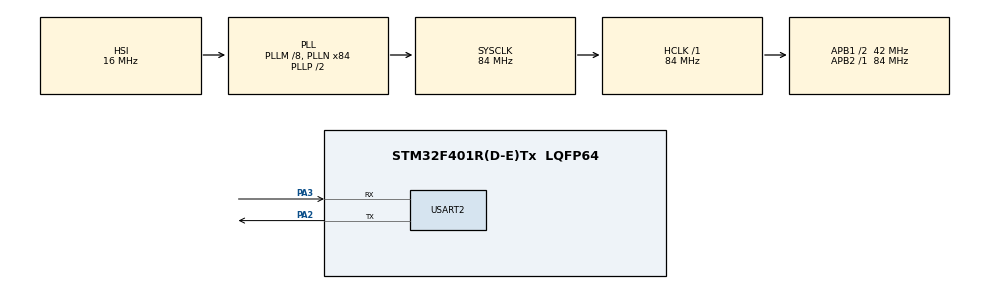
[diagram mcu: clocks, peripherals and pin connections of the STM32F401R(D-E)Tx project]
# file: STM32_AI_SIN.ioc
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Mcu.Family=STM32F4
Mcu.Name=STM32F401R(D-E)Tx
Mcu.Package=LQFP64
NVIC.PriorityGroup=NVIC_PRIORITYGROUP_4
NVIC.TIM1_TRG_COM_TIM11_IRQn=true\:0\:0\:false\:false\:true\:true\:true\:true
NVIC.USART2_IRQn=true\:0\:0\:false\:false\:true\:true\:true\:true
PA13.Mode=Serial_Wire
PA13.Signal=SYS_JTMS-SWDIO
PA14.Mode=Serial_Wire
PA14.Signal=SYS_JTCK-SWCLK
PA2.Mode=Asynchronous
PA2.Signal=USART2_TX
PA3.Mode=Asynchronous
PA3.Signal=USART2_RX
PH0\ -\ OSC_IN.Mode=HSE-External-Oscillator
PH0\ -\ OSC_IN.Signal=RCC_OSC_IN
PH1\ -\ OSC_OUT.Mode=HSE-External-Oscillator
PH1\ -\ OSC_OUT.Signal=RCC_OSC_OUT
ProjectManager.HeapSize=0x800
ProjectManager.StackSize=0x800
ProjectManager.TargetToolchain=STM32CubeIDE
RCC.48MHZClocksFreq_Value=42000000
RCC.AHBFreq_Value=84000000
RCC.APB1CLKDivider=RCC_HCLK_DIV2
RCC.APB1Freq_Value=42000000
RCC.APB1TimFreq_Value=84000000
RCC.APB2Freq_Value=84000000
RCC.APB2TimFreq_Value=84000000
RCC.CortexFreq_Value=84000000
RCC.HCLKFreq_Value=84000000
RCC.HSE_VALUE=25000000
RCC.HSI_VALUE=16000000
RCC.LSE_VALUE=32768
RCC.PLLM=8
RCC.PLLN=84
RCC.SYSCLKFreq_VALUE=84000000
RCC.SYSCLKSource=RCC_SYSCLKSOURCE_PLLCLK
RCC.VCOOutputFreq_Value=168000000
STMicroelectronics.X-CUBE-AI.8.1.0.ActivationBufferSizeList=4928
STMicroelectronics.X-CUBE-AI.8.1.0.ActivationBuffers=pool0
STMicroelectronics.X-CUBE-AI.8.1.0.ActivationNames=pool0
STMicroelectronics.X-CUBE-AI.8.1.0.ActivationSizes=AI_SINNET_DATA_ACTIVATION_1_SIZE
STMicroelectronics.X-CUBE-AI.8.1.0.HeapSize=0x800
STMicroelectronics.X-CUBE-AI.8.1.0.InternalRamActivationBufferMaxSize=AI_SINNET_DATA_ACTIVATIONS_SIZE
STMicroelectronics.X-CUBE-AI.8.1.0.LatestDirectoryUsed-b5e6d1a6911b70669444c67b1f081640bab3704ab8a9a7e3d65810467d735324=C\:\\Users\\danie\\OneDrive\\Desktop\\STM32_AI_SIN\\experiments\\run_12_12_2023__17_07_38
STMicroelectronics.X-CUBE-AI.8.1.0.MaximumNumberOfInputLayer=1
STMicroelectronics.X-CUBE-AI.8.1.0.MaximumNumberOfOutputLayer=1
STMicroelectronics.X-CUBE-AI.8.1.0.MaximumSizeOfInputLayer=1
STMicroelectronics.X-CUBE-AI.8.1.0.MaximumSizeOfOutputLayer=1
STMicroelectronics.X-CUBE-AI.8.1.0.ModelActualCompression-b5e6d1a6911b70669444c67b1f081640bab3704ab8a9a7e3d65810467d735324=0.0
STMicroelectronics.X-CUBE-AI.8.1.0.ModelCompression-b5e6d1a6911b70669444c67b1f081640bab3704ab8a9a7e3d65810467d735324=None
STMicroelectronics.X-CUBE-AI.8.1.0.ModelFlashOccupation-b5e6d1a6911b70669444c67b1f081640bab3704ab8a9a7e3d65810467d735324=92974
STMicroelectronics.X-CUBE-AI.8.1.0.ModelHashList=b5e6d1a6911b70669444c67b1f081640bab3704ab8a9a7e3d65810467d735324
STMicroelectronics.X-CUBE-AI.8.1.0.ModelKind-b5e6d1a6911b70669444c67b1f081640bab3704ab8a9a7e3d65810467d735324=ONNX
STMicroelectronics.X-CUBE-AI.8.1.0.ModelMacc-b5e6d1a6911b70669444c67b1f081640bab3704ab8a9a7e3d65810467d735324=74767
STMicroelectronics.X-CUBE-AI.8.1.0.ModelName-b5e6d1a6911b70669444c67b1f081640bab3704ab8a9a7e3d65810467d735324=sinnet
STMicroelectronics.X-CUBE-AI.8.1.0.ModelNameList=sinnet
STMicroelectronics.X-CUBE-AI.8.1.0.ModelRamOccupation-b5e6d1a6911b70669444c67b1f081640bab3704ab8a9a7e3d65810467d735324=4928
STMicroelectronics.X-CUBE-AI.8.1.0.ModelStructureFile-b5e6d1a6911b70669444c67b1f081640bab3704ab8a9a7e3d65810467d735324=C\:\\Users\\danie\\OneDrive\\Desktop\\STM32_AI_SIN\\experiments\\run_12_12_2023__17_07_38\\model_int8.onnx
STMicroelectronics.X-CUBE-AI.8.1.0.ModelType-b5e6d1a6911b70669444c67b1f081640bab3704ab8a9a7e3d65810467d735324=Saved model
STMicroelectronics.X-CUBE-AI.8.1.0.ReadyForCodeGeneration=true
STMicroelectronics.X-CUBE-AI.8.1.0.StackSize=0x800
STMicroelectronics.X-CUBE-AI.8.1.0.WorkingBufferStartAddrList=0xFFFFFFFF
STMicroelectronics.X-CUBE-AI.8.1.0.XAaCUBEAaAICcArtificialOoIntelligenceJjCore=true
STMicroelectronics.X-CUBE-AI.8.1.0.copyWeightToRam-b5e6d1a6911b70669444c67b1f081640bab3704ab8a9a7e3d65810467d735324=false
STMicroelectronics.X-CUBE-AI.8.1.0.customLayerConfigEnabled-b5e6d1a6911b70669444c67b1f081640bab3704ab8a9a7e3d65810467d735324=false
STMicroelectronics.X-CUBE-AI.8.1.0.noOnnxIoTranspose-b5e6d1a6911b70669444c67b1f081640bab3704ab8a9a7e3d65810467d735324=false
STMicroelectronics.X-CUBE-AI.8.1.0.useInputAllocation-b5e6d1a6911b70669444c67b1f081640bab3704ab8a9a7e3d65810467d735324=true
STMicroelectronics.X-CUBE-AI.8.1.0.useOutputAllocation-b5e6d1a6911b70669444c67b1f081640bab3704ab8a9a7e3d65810467d735324=true
TIM11.Period=65536-1
TIM11.Prescaler=84-1
USART2.VirtualMode=VM_ASYNC
VP_CRC_VS_CRC.Mode=CRC_Activate
VP_STMicroelectronics.X-CUBE-AI_VS_ArtificialOoIntelligenceJjXAaCUBEAaAI_8.1.0.Mode=ArtificialOoIntelligenceJjXAaCUBEAaAI
VP_TIM11_VS_ClockSourceINT.Mode=Enable_Timer
board=custom

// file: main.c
/* USER CODE BEGIN Header */
/**
  ******************************************************************************
  * @file           : main.c
  * @brief          : Main program body
  ******************************************************************************
  * @attention
  *
  * Copyright (c) 2023 STMicroelectronics.
  * All rights reserved.
  *
  * This software is licensed under terms that can be found in the LICENSE file
  * in the root directory of this software component.
  * If no LICENSE file comes with this software, it is provided AS-IS.
  *
  ******************************************************************************
  */
/* USER CODE END Header */
#include "main.h"

/* USER CODE BEGIN Includes */
#include <math.h>
#include <stdio.h>
#include "sinnet.h"
#include "sinnet_data.h"
/* USER CODE END Includes */

/* USER CODE BEGIN PD */
#define MAX_STRING_LENGTH 255
#define APB2_FREQUENCY 84000000
/* USER CODE END PD */

CRC_HandleTypeDef hcrc;

TIM_HandleTypeDef htim11;

UART_HandleTypeDef huart2;

/* USER CODE BEGIN PV */
ai_handle network = AI_HANDLE_NULL;
ai_float activations[AI_SINNET_DATA_ACTIVATIONS_SIZE];
ai_float in_data[AI_SINNET_IN_1_SIZE];
ai_float out_data[AI_SINNET_OUT_1_SIZE];

ai_buffer *ai_input;
ai_buffer *ai_output;

/* USER CODE END PV */

void SystemClock_Config(void);
static void MX_GPIO_Init(void);
static void MX_CRC_Init(void);
static void MX_TIM11_Init(void);
static void MX_USART2_UART_Init(void);

/* USER CODE BEGIN 0 */
void ai_init(void){
  ai_network_params params;
  ai_error ai_err;

  ai_err = ai_sinnet_create(&network, AI_SINNET_DATA_CONFIG);
  if (ai_err.type != AI_ERROR_NONE)
	{
	  while(1);
	}

  if (!ai_sinnet_data_params_get(&params)){
	  while(1);
  }

  AI_BUFFER_ARRAY_ITEM_SET_ADDRESS(&params.map_activations, 0, activations);

  if (!ai_sinnet_init(network, &params))
    {
      while(1);
    }

  ai_input = ai_sinnet_inputs_get(network, NULL);
  ai_output = ai_sinnet_outputs_get(network, NULL);

  ai_network_report report;
  ai_sinnet_get_report(network, &report);
}

int ai_run(const void *in_data, void *out_data){
  ai_i32 n_batch;
  ai_error err;

  ai_input[0].data = AI_HANDLE_PTR(in_data);
  ai_output[0].data = AI_HANDLE_PTR(out_data);
  n_batch = ai_sinnet_run(network, &ai_input[0], &ai_output[0]);

  if (n_batch <= 0) {
	char msg[MAX_STRING_LENGTH];

    err = ai_sinnet_get_error(network);
    sprintf(msg, "E: AI error - type=0x%x code=0x%x\r\n", err.type, err.code);
    HAL_UART_Transmit(&huart2, (const uint8_t *) msg, strlen(msg), HAL_MAX_DELAY);
    return -1;
  };

  return 0;
}

int ai_forward(const void *in_data, const void *out_data){
	ai_i32 n_batch;
    ai_error err;

    ai_input[0].data = AI_HANDLE_PTR(in_data);
    ai_output[0].data = AI_HANDLE_PTR(out_data);
    n_batch = ai_sinnet_forward(network, &ai_input[0]);

    if (n_batch <= 0) {
    	char msg[MAX_STRING_LENGTH];

        err = ai_sinnet_get_error(network);
        sprintf(msg, "E: AI error - type=0x%x code=0x%x\r\n", err.type, err.code);
        HAL_UART_Transmit(&huart2, (const uint8_t *) msg, strlen(msg), HAL_MAX_DELAY);
        return -1;
      };

    ai_output = ai_sinnet_outputs_get(network, NULL);
    return 0;

}
/* USER CODE END 0 */

int main(void)
{
  /* USER CODE BEGIN 1 */
  uint32_t start_count;
  uint32_t current_count;
  uint32_t elapsed_time;

  double step_size = 0.05 * M_PI;
  int total_steps = (int)(2 * M_PI / step_size);

  /* USER CODE END 1 */

  /* MCU Configuration--------------------------------------------------------*/

  /* Reset of all peripherals, Initializes the Flash interface and the Systick. */
  HAL_Init();

  /* Configure the system clock */
  SystemClock_Config();

  /* Initialize all configured peripherals */
  MX_GPIO_Init();
  MX_CRC_Init();
  MX_TIM11_Init();
  MX_USART2_UART_Init();
  /* USER CODE BEGIN 2 */

  HAL_TIM_Base_Start(&htim11);

  ai_init();

  char msg[MAX_STRING_LENGTH] = "Started!";
  HAL_UART_Transmit(&huart2, (const uint8_t *) msg, strlen(msg), HAL_MAX_DELAY);

  /* USER CODE END 2 */

  /* Infinite loop */
  /* USER CODE BEGIN WHILE */
  while (1)
  {
	  for (int i = 0; i <= total_steps; ++i) {
		  ((ai_float *) in_data)[0] = (ai_float) i * step_size;

		  //ai_forward(in_data, out_data);

		  start_count = htim11.Instance->CNT;
		  ai_run(in_data, out_data);
		  current_count = htim11.Instance->CNT;

		  float predictions = ((float *)out_data)[0];
		  elapsed_time = (current_count - start_count);

		  float elapsed_ns = (float) elapsed_time / (APB2_FREQUENCY / 1000000);
		  char message[MAX_STRING_LENGTH] = "";
		  sprintf(message, "Input: %f - Output: %f - Expected output: %f - elapsed time: %f us\n", in_data[0], predictions, sin(in_data[0]), elapsed_ns);
		  HAL_UART_Transmit(&huart2, (const uint8_t *) message, strlen(message), HAL_MAX_DELAY);

	  }
	  HAL_Delay(5000);

    /* USER CODE END WHILE */

  }
}

void SystemClock_Config(void)
{
  RCC_OscInitTypeDef RCC_OscInitStruct = {0};
  RCC_ClkInitTypeDef RCC_ClkInitStruct = {0};

  /** Configure the main internal regulator output voltage
  */
  __HAL_RCC_PWR_CLK_ENABLE();
  __HAL_PWR_VOLTAGESCALING_CONFIG(PWR_REGULATOR_VOLTAGE_SCALE2);

  /** Initializes the RCC Oscillators according to the specified parameters
  * in the RCC_OscInitTypeDef structure.
  */
  RCC_OscInitStruct.OscillatorType = RCC_OSCILLATORTYPE_HSI;
  RCC_OscInitStruct.HSIState = RCC_HSI_ON;
  RCC_OscInitStruct.HSICalibrationValue = RCC_HSICALIBRATION_DEFAULT;
  RCC_OscInitStruct.PLL.PLLState = RCC_PLL_ON;
  RCC_OscInitStruct.PLL.PLLSource = RCC_PLLSOURCE_HSI;
  RCC_OscInitStruct.PLL.PLLM = 8;
  RCC_OscInitStruct.PLL.PLLN = 84;
  RCC_OscInitStruct.PLL.PLLP = RCC_PLLP_DIV2;
  RCC_OscInitStruct.PLL.PLLQ = 4;
  if (HAL_RCC_OscConfig(&RCC_OscInitStruct) != HAL_OK)
  {
    Error_Handler();
  }

  /** Initializes the CPU, AHB and APB buses clocks
  */
  RCC_ClkInitStruct.ClockType = RCC_CLOCKTYPE_HCLK|RCC_CLOCKTYPE_SYSCLK
                              |RCC_CLOCKTYPE_PCLK1|RCC_CLOCKTYPE_PCLK2;
  RCC_ClkInitStruct.SYSCLKSource = RCC_SYSCLKSOURCE_PLLCLK;
  RCC_ClkInitStruct.AHBCLKDivider = RCC_SYSCLK_DIV1;
  RCC_ClkInitStruct.APB1CLKDivider = RCC_HCLK_DIV2;
  RCC_ClkInitStruct.APB2CLKDivider = RCC_HCLK_DIV1;

  if (HAL_RCC_ClockConfig(&RCC_ClkInitStruct, FLASH_LATENCY_2) != HAL_OK)
  {
    Error_Handler();
  }
}

static void MX_CRC_Init(void)
{

  hcrc.Instance = CRC;
  if (HAL_CRC_Init(&hcrc) != HAL_OK)
  {
    Error_Handler();
  }

}

static void MX_TIM11_Init(void)
{

  htim11.Instance = TIM11;
  htim11.Init.Prescaler = 84-1;
  htim11.Init.CounterMode = TIM_COUNTERMODE_UP;
  htim11.Init.Period = 65536-1;
  htim11.Init.ClockDivision = TIM_CLOCKDIVISION_DIV1;
  htim11.Init.AutoReloadPreload = TIM_AUTORELOAD_PRELOAD_DISABLE;
  if (HAL_TIM_Base_Init(&htim11) != HAL_OK)
  {
    Error_Handler();
  }

}

static void MX_USART2_UART_Init(void)
{

  huart2.Instance = USART2;
  huart2.Init.BaudRate = 115200;
  huart2.Init.WordLength = UART_WORDLENGTH_8B;
  huart2.Init.StopBits = UART_STOPBITS_1;
  huart2.Init.Parity = UART_PARITY_NONE;
  huart2.Init.Mode = UART_MODE_TX_RX;
  huart2.Init.HwFlowCtl = UART_HWCONTROL_NONE;
  huart2.Init.OverSampling = UART_OVERSAMPLING_16;
  if (HAL_UART_Init(&huart2) != HAL_OK)
  {
    Error_Handler();
  }

}

static void MX_GPIO_Init(void)
{

  /* GPIO Ports Clock Enable */
  __HAL_RCC_GPIOH_CLK_ENABLE();
  __HAL_RCC_GPIOA_CLK_ENABLE();

}

void Error_Handler(void)
{
  __disable_irq();
  while (1)
  {
  }
}
